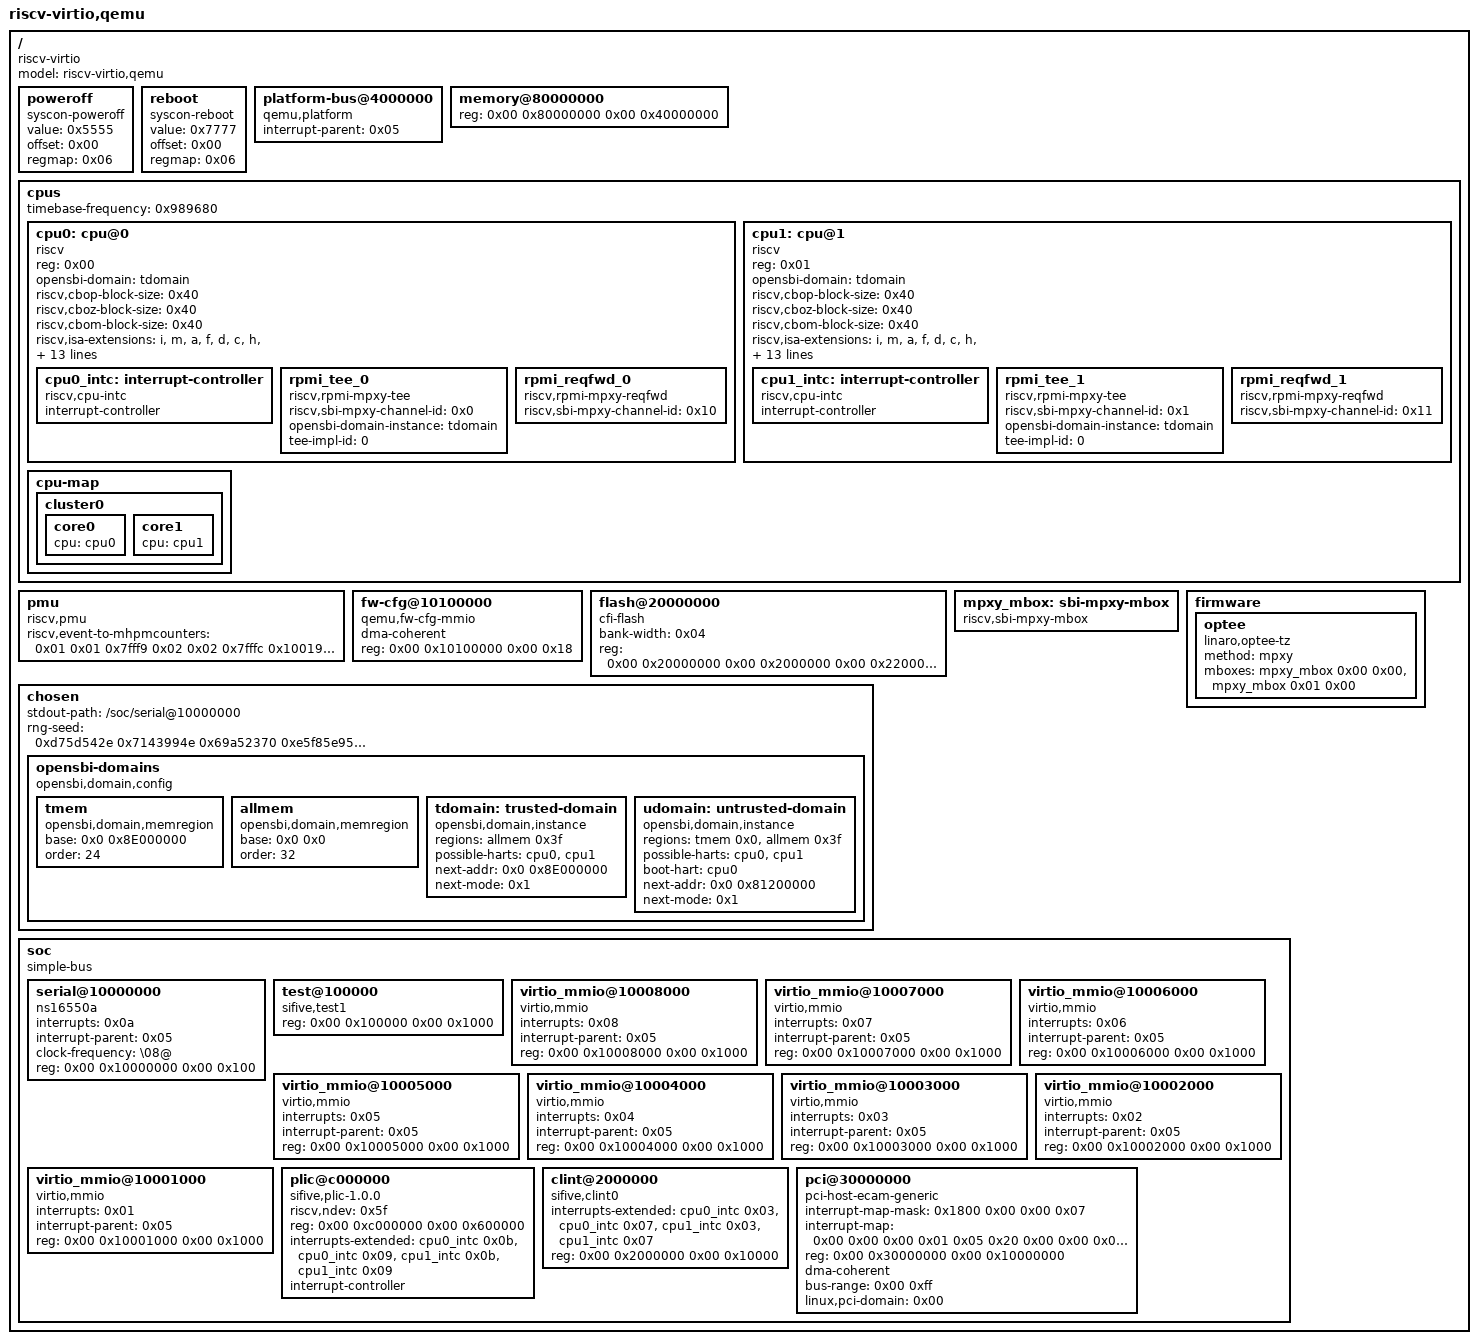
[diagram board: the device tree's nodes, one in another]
// QEMU's virt machine with 2 RV32 harts, OP-TEE in a trusted OpenSBI
// domain: qemu_rv64_virt_domain.dts for qemu-system-riscv32, OP-TEE's
// build.git qemu_riscv32 (-cpu rv32,zkr=on -smp 2 -m 1024).
//
// The harts, memory and PCI nodes are QEMU 10.0.0's, from
//   qemu-system-riscv32 -machine virt,dumpdtb=virt.dtb -cpu rv32,zkr=on \
//     -smp 2 -m 1024
// The other nodes are as in qemu_rv64_virt_domain.dts (without QEMU's RTC
// and aliases, as there), and so are the domains, MPXY channels and OP-TEE
// node, except where RV32 differs:
// - allmem: OpenSBI takes a region's order up to XLEN, 32 here
// - OP-TEE's memory: plat-virt's default 0x8e000000, as RAM ends at
//   0xc0000000 (Linux maps 1 GiB at most on RV32)

/dts-v1/;

/ {
	#address-cells = <0x02>;
	#size-cells = <0x02>;
	compatible = "riscv-virtio";
	model = "riscv-virtio,qemu";

	poweroff {
		value = <0x5555>;
		offset = <0x00>;
		regmap = <0x06>;
		compatible = "syscon-poweroff";
	};

	reboot {
		value = <0x7777>;
		offset = <0x00>;
		regmap = <0x06>;
		compatible = "syscon-reboot";
	};

	platform-bus@4000000 {
		interrupt-parent = <0x05>;
		ranges = <0x00 0x00 0x4000000 0x2000000>;
		#address-cells = <0x01>;
		#size-cells = <0x01>;
		compatible = "qemu,platform\0simple-bus";
	};

	memory@80000000 {
		device_type = "memory";
		reg = <0x00 0x80000000 0x00 0x40000000>;
	};

	cpus {
		#address-cells = <0x01>;
		#size-cells = <0x00>;
		timebase-frequency = <0x989680>;

		cpu0: cpu@0 {
			phandle = <0x03>;
			device_type = "cpu";
			reg = <0x00>;
			status = "okay";
			compatible = "riscv";
			opensbi-domain = <&tdomain>;
			riscv,cbop-block-size = <0x40>;
			riscv,cboz-block-size = <0x40>;
			riscv,cbom-block-size = <0x40>;
			riscv,isa-extensions = "i", "m", "a", "f", "d", "c", "h",
					       "zic64b", "zicbom", "zicbop", "zicboz", "ziccamoa",
					       "ziccif", "zicclsm", "ziccrse", "zicntr", "zicsr",
					       "zifencei", "zihintntl", "zihintpause", "zihpm",
					       "zmmul", "za64rs", "zaamo", "zalrsc", "zawrs", "zfa",
					       "zca", "zcf", "zcd", "zba", "zbb", "zbc", "zbs", "zkr",
					       "shcounterenw", "shgatpa", "shtvala", "shvsatpa",
					       "shvstvala", "shvstvecd", "ssccptr", "sscounterenw",
					       "sstc", "sstvala", "sstvecd", "ssu64xl", "svadu",
					       "svvptc";
			riscv,isa-base = "rv32i";
			riscv,isa = "rv32imafdch_zic64b_zicbom_zicbop_zicboz_ziccamoa_ziccif_zicclsm_ziccrse_zicntr_zicsr_zifencei_zihintntl_zihintpause_zihpm_zmmul_za64rs_zaamo_zalrsc_zawrs_zfa_zca_zcf_zcd_zba_zbb_zbc_zbs_zkr_shcounterenw_shgatpa_shtvala_shvsatpa_shvstvala_shvstvecd_ssccptr_sscounterenw_sstc_sstvala_sstvecd_ssu64xl_svadu_svvptc";
			mmu-type = "riscv,sv32";

			cpu0_intc: interrupt-controller {
				#interrupt-cells = <0x01>;
				interrupt-controller;
				compatible = "riscv,cpu-intc";
			};
			rpmi_tee_0 {
				compatible = "riscv,rpmi-mpxy-tee";
				riscv,sbi-mpxy-channel-id = <0x0>;
				opensbi-domain-instance = <&tdomain>;
				tee-impl-id = <0>;
			};
			rpmi_reqfwd_0 {
				compatible = "riscv,rpmi-mpxy-reqfwd";
				riscv,sbi-mpxy-channel-id = <0x10>;
			};
		};

		cpu1: cpu@1 {
			phandle = <0x01>;
			device_type = "cpu";
			reg = <0x01>;
			status = "okay";
			compatible = "riscv";
			opensbi-domain = <&tdomain>;
			riscv,cbop-block-size = <0x40>;
			riscv,cboz-block-size = <0x40>;
			riscv,cbom-block-size = <0x40>;
			riscv,isa-extensions = "i", "m", "a", "f", "d", "c", "h",
					       "zic64b", "zicbom", "zicbop", "zicboz", "ziccamoa",
					       "ziccif", "zicclsm", "ziccrse", "zicntr", "zicsr",
					       "zifencei", "zihintntl", "zihintpause", "zihpm",
					       "zmmul", "za64rs", "zaamo", "zalrsc", "zawrs", "zfa",
					       "zca", "zcf", "zcd", "zba", "zbb", "zbc", "zbs", "zkr",
					       "shcounterenw", "shgatpa", "shtvala", "shvsatpa",
					       "shvstvala", "shvstvecd", "ssccptr", "sscounterenw",
					       "sstc", "sstvala", "sstvecd", "ssu64xl", "svadu",
					       "svvptc";
			riscv,isa-base = "rv32i";
			riscv,isa = "rv32imafdch_zic64b_zicbom_zicbop_zicboz_ziccamoa_ziccif_zicclsm_ziccrse_zicntr_zicsr_zifencei_zihintntl_zihintpause_zihpm_zmmul_za64rs_zaamo_zalrsc_zawrs_zfa_zca_zcf_zcd_zba_zbb_zbc_zbs_zkr_shcounterenw_shgatpa_shtvala_shvsatpa_shvstvala_shvstvecd_ssccptr_sscounterenw_sstc_sstvala_sstvecd_ssu64xl_svadu_svvptc";
			mmu-type = "riscv,sv32";

			cpu1_intc: interrupt-controller {
				#interrupt-cells = <0x01>;
				interrupt-controller;
				compatible = "riscv,cpu-intc";
			};
			rpmi_tee_1 {
				compatible = "riscv,rpmi-mpxy-tee";
				riscv,sbi-mpxy-channel-id = <0x1>;
				opensbi-domain-instance = <&tdomain>;
				tee-impl-id = <0>;
			};
			rpmi_reqfwd_1 {
				compatible = "riscv,rpmi-mpxy-reqfwd";
				riscv,sbi-mpxy-channel-id = <0x11>;
			};

		};

		cpu-map {

			cluster0 {

				core0 {
					cpu = <&cpu0>;
				};

				core1 {
					cpu = <&cpu1>;
				};
			};
		};
	};

	pmu {
		riscv,event-to-mhpmcounters = <0x01 0x01 0x7fff9 0x02 0x02 0x7fffc 0x10019 0x10019 0x7fff8 0x1001b 0x1001b 0x7fff8 0x10021 0x10021 0x7fff8>;
		compatible = "riscv,pmu";
	};

	fw-cfg@10100000 {
		dma-coherent;
		reg = <0x00 0x10100000 0x00 0x18>;
		compatible = "qemu,fw-cfg-mmio";
	};

	flash@20000000 {
		bank-width = <0x04>;
		reg = <0x00 0x20000000 0x00 0x2000000 0x00 0x22000000 0x00 0x2000000>;
		compatible = "cfi-flash";
	};

	chosen {
		stdout-path = "/soc/serial@10000000";
		rng-seed = <0xd75d542e 0x7143994e 0x69a52370 0xe5f85e95 0xc16954a8 0xffe952e9 0x5a9b5b6f 0xe7f1b07>;

		opensbi-domains {
			compatible = "opensbi,domain,config";

			tmem: tmem {
				compatible = "opensbi,domain,memregion";
				base = <0x0 0x8E000000>;
				order = <24>; // 16MiB
			};

			allmem: allmem {
				compatible = "opensbi,domain,memregion";
				base = <0x0 0x0>;
				order = <32>;
			};

			tdomain: trusted-domain {
				compatible = "opensbi,domain,instance";
				regions = <&allmem 0x3f>;
				possible-harts = <&cpu0 &cpu1>;
				next-addr = <0x0 0x8E000000>; /* optee_os: CFG_TDDRAM_START */
				next-mode = <0x1>;
			};

			udomain: untrusted-domain {
				compatible = "opensbi,domain,instance";
				regions = <&tmem 0x0>, <&allmem 0x3f>;
				possible-harts = <&cpu0 &cpu1>;
				boot-hart = <&cpu0>;
				next-addr = <0x0 0x81200000>; /* u-boot: CONFIG_TEXT_BASE */
				next-mode = <0x1>;
			};
		};
	};

	mpxy_mbox: sbi-mpxy-mbox {
		compatible = "riscv,sbi-mpxy-mbox";
		#mbox-cells = <2>;
	};

	firmware {
		optee {
			compatible = "linaro,optee-tz";
			method = "mpxy";
			mboxes = <&mpxy_mbox 0x00 0x00>, <&mpxy_mbox 0x01 0x00>;
		};
	};

	soc {
		#address-cells = <0x02>;
		#size-cells = <0x02>;
		compatible = "simple-bus";
		ranges;

		serial@10000000 {
			interrupts = <0x0a>;
			interrupt-parent = <0x05>;
			clock-frequency = "\08@";
			reg = <0x00 0x10000000 0x00 0x100>;
			compatible = "ns16550a";
		};

		test@100000 {
			phandle = <0x06>;
			reg = <0x00 0x100000 0x00 0x1000>;
			compatible = "sifive,test1\0sifive,test0\0syscon";
		};

		virtio_mmio@10008000 {
			interrupts = <0x08>;
			interrupt-parent = <0x05>;
			reg = <0x00 0x10008000 0x00 0x1000>;
			compatible = "virtio,mmio";
		};

		virtio_mmio@10007000 {
			interrupts = <0x07>;
			interrupt-parent = <0x05>;
			reg = <0x00 0x10007000 0x00 0x1000>;
			compatible = "virtio,mmio";
		};

		virtio_mmio@10006000 {
			interrupts = <0x06>;
			interrupt-parent = <0x05>;
			reg = <0x00 0x10006000 0x00 0x1000>;
			compatible = "virtio,mmio";
		};

		virtio_mmio@10005000 {
			interrupts = <0x05>;
			interrupt-parent = <0x05>;
			reg = <0x00 0x10005000 0x00 0x1000>;
			compatible = "virtio,mmio";
		};

		virtio_mmio@10004000 {
			interrupts = <0x04>;
			interrupt-parent = <0x05>;
			reg = <0x00 0x10004000 0x00 0x1000>;
			compatible = "virtio,mmio";
		};

		virtio_mmio@10003000 {
			interrupts = <0x03>;
			interrupt-parent = <0x05>;
			reg = <0x00 0x10003000 0x00 0x1000>;
			compatible = "virtio,mmio";
		};

		virtio_mmio@10002000 {
			interrupts = <0x02>;
			interrupt-parent = <0x05>;
			reg = <0x00 0x10002000 0x00 0x1000>;
			compatible = "virtio,mmio";
		};

		virtio_mmio@10001000 {
			interrupts = <0x01>;
			interrupt-parent = <0x05>;
			reg = <0x00 0x10001000 0x00 0x1000>;
			compatible = "virtio,mmio";
		};

		plic@c000000 {
			phandle = <0x05>;
			riscv,ndev = <0x5f>;
			reg = <0x00 0xc000000 0x00 0x600000>;
			interrupts-extended = <&cpu0_intc 0x0b &cpu0_intc 0x09
					       &cpu1_intc 0x0b &cpu1_intc 0x09>;
			interrupt-controller;
			compatible = "sifive,plic-1.0.0\0riscv,plic0";
			#address-cells = <0x00>;
			#interrupt-cells = <0x01>;
		};

		clint@2000000 {
			interrupts-extended = <&cpu0_intc 0x03 &cpu0_intc 0x07
					       &cpu1_intc 0x03 &cpu1_intc 0x07>;
			reg = <0x00 0x2000000 0x00 0x10000>;
			compatible = "sifive,clint0\0riscv,clint0";
		};

		pci@30000000 {
			interrupt-map-mask = <0x1800 0x00 0x00 0x07>;
			interrupt-map = <0x00 0x00 0x00 0x01 0x05 0x20 0x00 0x00 0x00 0x02 0x05 0x21 0x00 0x00 0x00 0x03 0x05 0x22 0x00 0x00 0x00 0x04 0x05 0x23 0x800 0x00 0x00 0x01 0x05 0x21 0x800 0x00 0x00 0x02 0x05 0x22 0x800 0x00 0x00 0x03 0x05 0x23 0x800 0x00 0x00 0x04 0x05 0x20 0x1000 0x00 0x00 0x01 0x05 0x22 0x1000 0x00 0x00 0x02 0x05 0x23 0x1000 0x00 0x00 0x03 0x05 0x20 0x1000 0x00 0x00 0x04 0x05 0x21 0x1800 0x00 0x00 0x01 0x05 0x23 0x1800 0x00 0x00 0x02 0x05 0x20 0x1800 0x00 0x00 0x03 0x05 0x21 0x1800 0x00 0x00 0x04 0x05 0x22>;
			ranges = <0x1000000 0x00 0x00 0x00 0x3000000 0x00 0x10000 0x2000000 0x00 0x40000000 0x00 0x40000000 0x00 0x40000000 0x3000000 0x03 0x00 0x03 0x00 0x01 0x00>;
			reg = <0x00 0x30000000 0x00 0x10000000>;
			dma-coherent;
			bus-range = <0x00 0xff>;
			linux,pci-domain = <0x00>;
			device_type = "pci";
			compatible = "pci-host-ecam-generic";
			#size-cells = <0x02>;
			#interrupt-cells = <0x01>;
			#address-cells = <0x03>;
		};
	};
};
